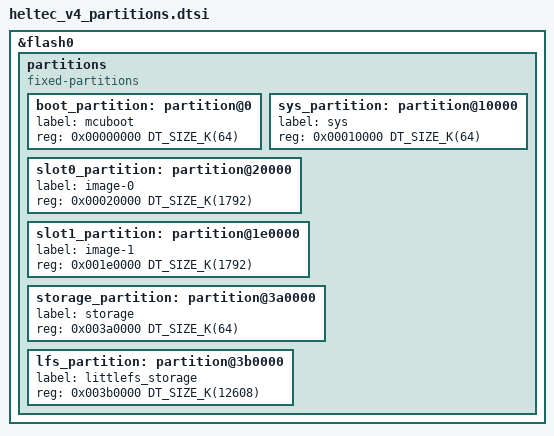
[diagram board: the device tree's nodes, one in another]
/*
 * Flash partition table for the Heltec WiFi LoRa 32 V4 (ESP32-S3R2, 16 MB
 * external quad flash).
 *
 * SPDX-License-Identifier: Apache-2.0
 *
 * Shared by the application image and the MCUboot image, for the same reason
 * as esp32s3_partitions.dtsi: sysbuild builds MCUboot with its own devicetree,
 * and one fragment is what stops the two disagreeing about the slots.
 *
 * **Identical to esp32s3_partitions.dtsi up to lfs_partition**, which simply
 * takes the extra 8 MB. The slots stay at 1792 KB rather than growing with the
 * part: the application is the same image as on the XIAO ESP32S3 (~800 KB,
 * WiFi included) plus, later, an optional display, and keeping the two tables
 * the same shape keeps the ElegantOTA headroom argument in that file valid
 * here too. Growing a slot later moves lfs_partition and reformats every
 * deployed board's bundle store, so this is decided once.
 *
 *   0x000000     64K  boot_partition     MCUboot
 *   0x010000     64K  sys_partition      vendor slot, kept
 *   0x020000   1792K  slot0_partition    image-0
 *   0x1E0000   1792K  slot1_partition    image-1
 *   0x3A0000     64K  storage_partition  settings
 *   0x3B0000  12608K  lfs_partition      LittleFS - the firmware bundles
 *
 * The same caveat as on the XIAO applies: the filesystem shares the XIP flash
 * the CPU executes from. See boards/xiao_esp32s3_esp32s3_procpu.conf.
 */

&flash0 {
	/delete-node/ partitions;

	partitions {
		compatible = "fixed-partitions";
		#address-cells = <1>;
		#size-cells = <1>;

		boot_partition: partition@0 {
			label = "mcuboot";
			reg = <0x00000000 DT_SIZE_K(64)>;
		};

		sys_partition: partition@10000 {
			label = "sys";
			reg = <0x00010000 DT_SIZE_K(64)>;
		};

		slot0_partition: partition@20000 {
			label = "image-0";
			reg = <0x00020000 DT_SIZE_K(1792)>;
		};

		slot1_partition: partition@1e0000 {
			label = "image-1";
			reg = <0x001e0000 DT_SIZE_K(1792)>;
		};

		storage_partition: partition@3a0000 {
			label = "storage";
			reg = <0x003a0000 DT_SIZE_K(64)>;
		};

		/* Everything left: ~12.3 MB, roughly 28 bundles of 300-500 KB. */
		lfs_partition: partition@3b0000 {
			label = "littlefs_storage";
			reg = <0x003b0000 DT_SIZE_K(12608)>;
		};
	};
};
